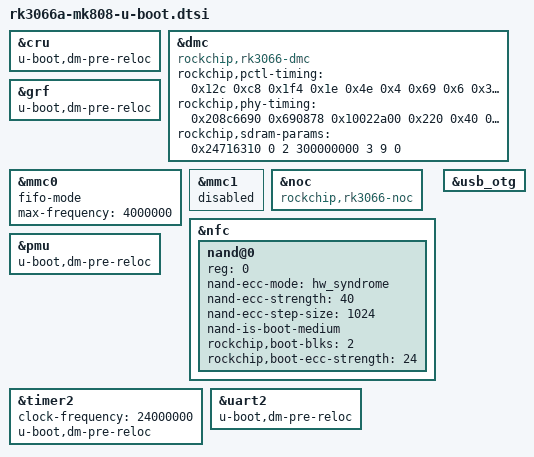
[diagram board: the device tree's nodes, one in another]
// SPDX-License-Identifier: (GPL-2.0+ OR MIT)

#include "rk3066a-u-boot.dtsi"

&cru {
	u-boot,dm-pre-reloc;
};

&dmc {
	compatible = "rockchip,rk3066-dmc", "syscon";
	rockchip,pctl-timing = <0x12c 0xc8 0x1f4 0x1e 0x4e 0x4 0x69 0x6
				0x3 0x0 0x6 0x5 0xc 0x10 0x6 0x4
				0x4 0x5 0x4 0x200 0x3 0xa 0x40 0x0
				0x1 0x5 0x5 0x3 0xc 0x1e 0x100 0x0
				0x4 0x0>;
	rockchip,phy-timing = <0x208c6690 0x690878 0x10022a00
			       0x220 0x40 0x0 0x0>;
	rockchip,sdram-params = <0x24716310 0 2 300000000 3 9 0>;
};

&grf {
	u-boot,dm-pre-reloc;
};

&mmc0 {
	fifo-mode;
	max-frequency = <4000000>;
	u-boot,dm-spl;
};

&mmc1 {
	status = "disabled";
};

&noc {
	compatible = "rockchip,rk3066-noc", "syscon";
};

&nfc {
	u-boot,dm-spl;
	#address-cells = <1>;
	#size-cells = <0>;
	status = "okay";

	nand@0 {
		u-boot,dm-spl;
		reg = <0>;
		nand-ecc-mode = "hw_syndrome";
		nand-ecc-strength = <40>;
		nand-ecc-step-size = <1024>;
		nand-is-boot-medium;
		rockchip,boot-blks = <2>;
		rockchip,boot-ecc-strength = <24>;
	};
};

&noc {
	compatible = "rockchip,rk3066-noc", "syscon";
};

&pmu {
	u-boot,dm-pre-reloc;
};

&timer2 {
	clock-frequency = <24000000>;
	u-boot,dm-pre-reloc;
};

&uart2 {
	u-boot,dm-pre-reloc;
};

&usb_otg {
	u-boot,dm-spl;
};
